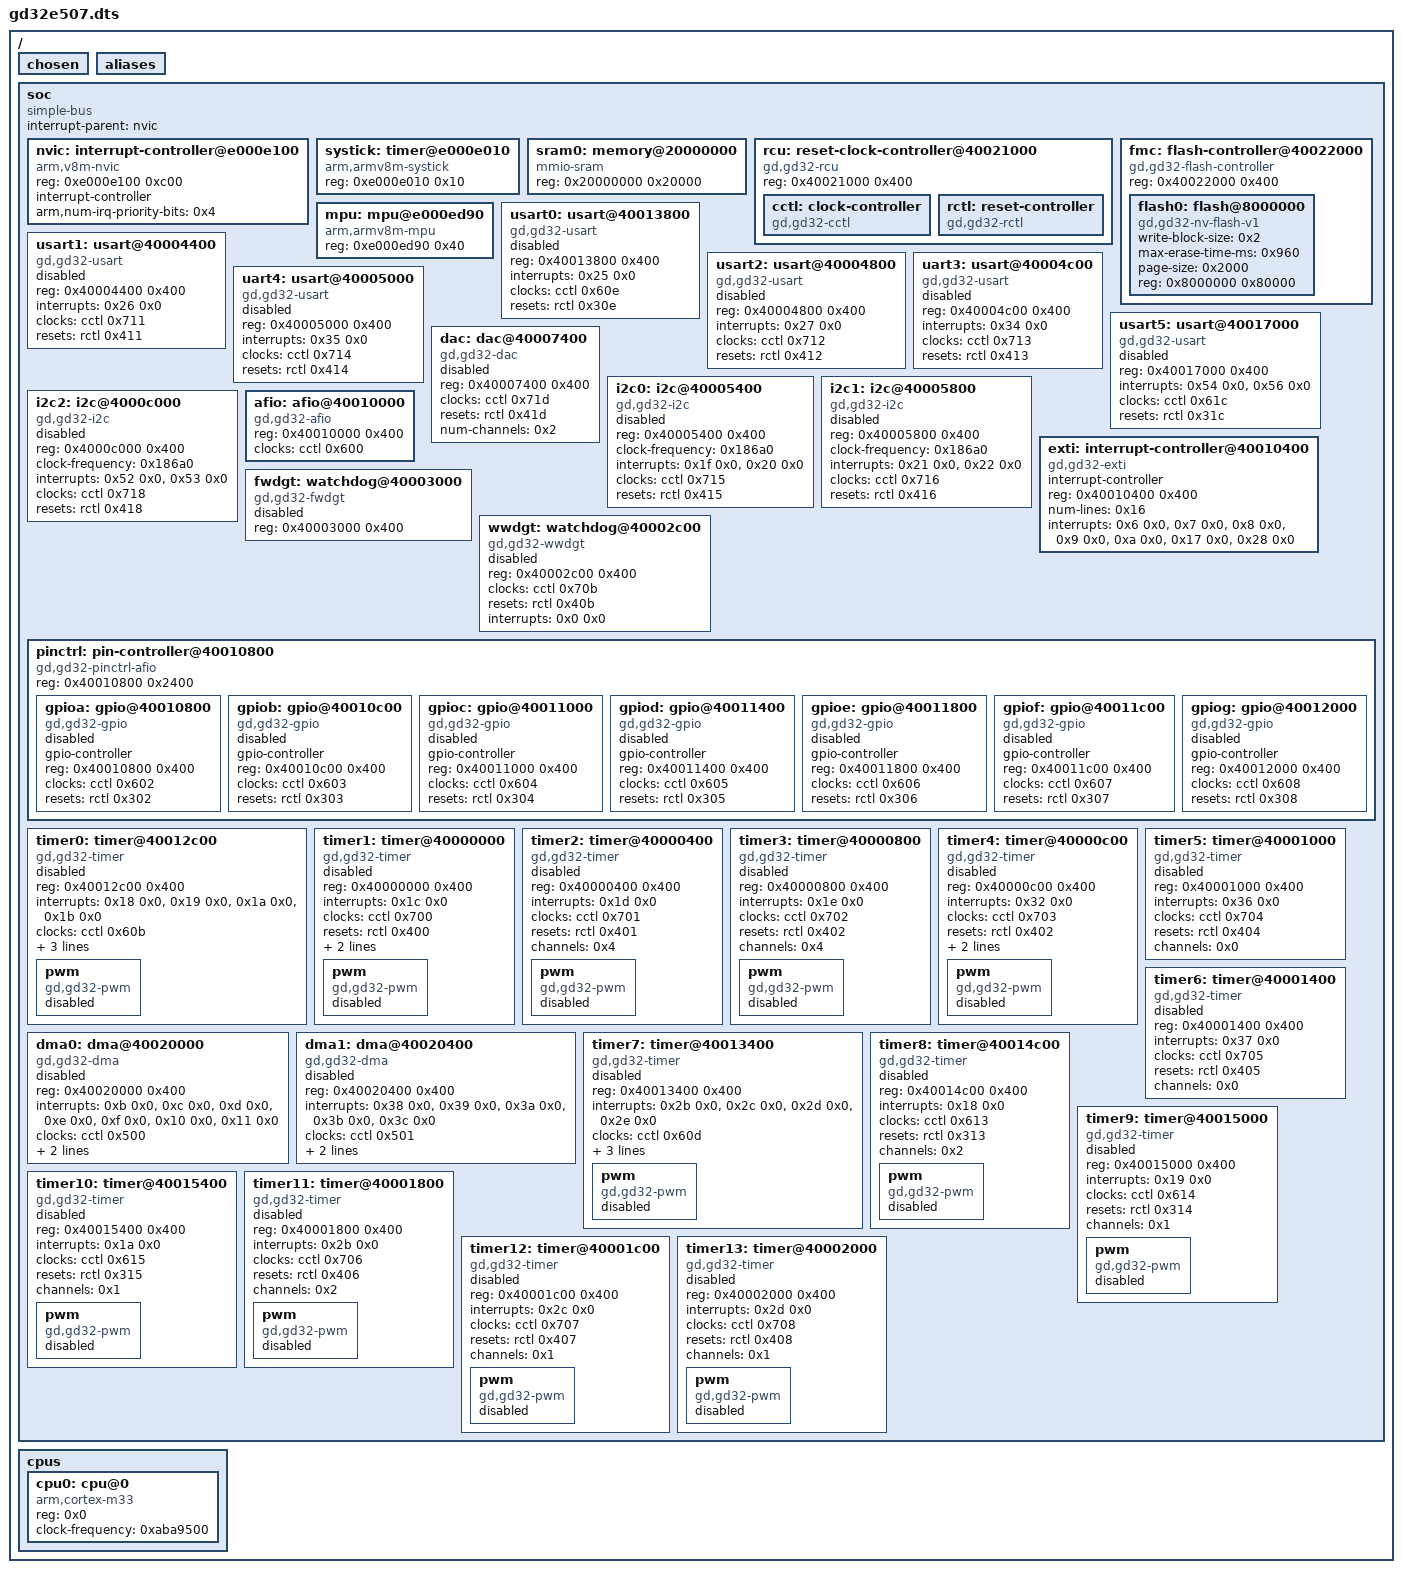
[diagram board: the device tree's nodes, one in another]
/dts-v1/;

/ {
	#address-cells = < 0x1 >;
	#size-cells = < 0x1 >;
	chosen {
	};
	aliases {
	};
	soc {
		#address-cells = < 0x1 >;
		#size-cells = < 0x1 >;
		compatible = "simple-bus";
		interrupt-parent = < &nvic >;
		ranges;
		nvic: interrupt-controller@e000e100 {
			#address-cells = < 0x1 >;
			compatible = "arm,v8m-nvic";
			reg = < 0xe000e100 0xc00 >;
			interrupt-controller;
			#interrupt-cells = < 0x2 >;
			arm,num-irq-priority-bits = < 0x4 >;
			phandle = < 0x1 >;
		};
		systick: timer@e000e010 {
			compatible = "arm,armv8m-systick";
			reg = < 0xe000e010 0x10 >;
		};
		sram0: memory@20000000 {
			compatible = "mmio-sram";
			reg = < 0x20000000 0x20000 >;
		};
		rcu: reset-clock-controller@40021000 {
			compatible = "gd,gd32-rcu";
			reg = < 0x40021000 0x400 >;
			status = "okay";
			cctl: clock-controller {
				compatible = "gd,gd32-cctl";
				#clock-cells = < 0x1 >;
				status = "okay";
				phandle = < 0x2 >;
			};
			rctl: reset-controller {
				compatible = "gd,gd32-rctl";
				#reset-cells = < 0x1 >;
				status = "okay";
				phandle = < 0x3 >;
			};
		};
		fmc: flash-controller@40022000 {
			compatible = "gd,gd32-flash-controller";
			reg = < 0x40022000 0x400 >;
			#address-cells = < 0x1 >;
			#size-cells = < 0x1 >;
			flash0: flash@8000000 {
				compatible = "gd,gd32-nv-flash-v1", "soc-nv-flash";
				write-block-size = < 0x2 >;
				max-erase-time-ms = < 0x960 >;
				page-size = < 0x2000 >;
				reg = < 0x8000000 0x80000 >;
			};
		};
		mpu: mpu@e000ed90 {
			compatible = "arm,armv8m-mpu";
			reg = < 0xe000ed90 0x40 >;
		};
		usart0: usart@40013800 {
			compatible = "gd,gd32-usart";
			reg = < 0x40013800 0x400 >;
			interrupts = < 0x25 0x0 >;
			clocks = < &cctl 0x60e >;
			resets = < &rctl 0x30e >;
			status = "disabled";
		};
		usart1: usart@40004400 {
			compatible = "gd,gd32-usart";
			reg = < 0x40004400 0x400 >;
			interrupts = < 0x26 0x0 >;
			clocks = < &cctl 0x711 >;
			resets = < &rctl 0x411 >;
			status = "disabled";
		};
		usart2: usart@40004800 {
			compatible = "gd,gd32-usart";
			reg = < 0x40004800 0x400 >;
			interrupts = < 0x27 0x0 >;
			clocks = < &cctl 0x712 >;
			resets = < &rctl 0x412 >;
			status = "disabled";
		};
		uart3: usart@40004c00 {
			compatible = "gd,gd32-usart";
			reg = < 0x40004c00 0x400 >;
			interrupts = < 0x34 0x0 >;
			clocks = < &cctl 0x713 >;
			resets = < &rctl 0x413 >;
			status = "disabled";
		};
		uart4: usart@40005000 {
			compatible = "gd,gd32-usart";
			reg = < 0x40005000 0x400 >;
			interrupts = < 0x35 0x0 >;
			clocks = < &cctl 0x714 >;
			resets = < &rctl 0x414 >;
			status = "disabled";
		};
		usart5: usart@40017000 {
			compatible = "gd,gd32-usart";
			reg = < 0x40017000 0x400 >;
			interrupts = < 0x54 0x0 >, < 0x56 0x0 >;
			interrupt-names = "global", "wkup";
			clocks = < &cctl 0x61c >;
			resets = < &rctl 0x31c >;
			status = "disabled";
		};
		dac: dac@40007400 {
			compatible = "gd,gd32-dac";
			reg = < 0x40007400 0x400 >;
			clocks = < &cctl 0x71d >;
			resets = < &rctl 0x41d >;
			num-channels = < 0x2 >;
			status = "disabled";
			#io-channel-cells = < 0x1 >;
		};
		i2c0: i2c@40005400 {
			compatible = "gd,gd32-i2c";
			reg = < 0x40005400 0x400 >;
			#address-cells = < 0x1 >;
			#size-cells = < 0x0 >;
			clock-frequency = < 0x186a0 >;
			interrupts = < 0x1f 0x0 >, < 0x20 0x0 >;
			interrupt-names = "event", "error";
			clocks = < &cctl 0x715 >;
			resets = < &rctl 0x415 >;
			status = "disabled";
		};
		i2c1: i2c@40005800 {
			compatible = "gd,gd32-i2c";
			reg = < 0x40005800 0x400 >;
			#address-cells = < 0x1 >;
			#size-cells = < 0x0 >;
			clock-frequency = < 0x186a0 >;
			interrupts = < 0x21 0x0 >, < 0x22 0x0 >;
			interrupt-names = "event", "error";
			clocks = < &cctl 0x716 >;
			resets = < &rctl 0x416 >;
			status = "disabled";
		};
		i2c2: i2c@4000c000 {
			compatible = "gd,gd32-i2c";
			reg = < 0x4000c000 0x400 >;
			#address-cells = < 0x1 >;
			#size-cells = < 0x0 >;
			clock-frequency = < 0x186a0 >;
			interrupts = < 0x52 0x0 >, < 0x53 0x0 >;
			interrupt-names = "event", "error";
			clocks = < &cctl 0x718 >;
			resets = < &rctl 0x418 >;
			status = "disabled";
		};
		exti: interrupt-controller@40010400 {
			compatible = "gd,gd32-exti";
			interrupt-controller;
			#interrupt-cells = < 0x1 >;
			reg = < 0x40010400 0x400 >;
			num-lines = < 0x16 >;
			interrupts = < 0x6 0x0 >, < 0x7 0x0 >, < 0x8 0x0 >, < 0x9 0x0 >, < 0xa 0x0 >, < 0x17 0x0 >, < 0x28 0x0 >;
			interrupt-names = "line0", "line1", "line2", "line3", "line4", "line5-9", "line10-15";
			status = "okay";
		};
		afio: afio@40010000 {
			compatible = "gd,gd32-afio";
			reg = < 0x40010000 0x400 >;
			clocks = < &cctl 0x600 >;
			status = "okay";
		};
		fwdgt: watchdog@40003000 {
			compatible = "gd,gd32-fwdgt";
			reg = < 0x40003000 0x400 >;
			status = "disabled";
		};
		wwdgt: watchdog@40002c00 {
			compatible = "gd,gd32-wwdgt";
			reg = < 0x40002c00 0x400 >;
			clocks = < &cctl 0x70b >;
			resets = < &rctl 0x40b >;
			interrupts = < 0x0 0x0 >;
			status = "disabled";
		};
		pinctrl: pin-controller@40010800 {
			compatible = "gd,gd32-pinctrl-afio";
			reg = < 0x40010800 0x2400 >;
			#address-cells = < 0x1 >;
			#size-cells = < 0x1 >;
			status = "okay";
			gpioa: gpio@40010800 {
				compatible = "gd,gd32-gpio";
				gpio-controller;
				#gpio-cells = < 0x2 >;
				reg = < 0x40010800 0x400 >;
				clocks = < &cctl 0x602 >;
				resets = < &rctl 0x302 >;
				status = "disabled";
			};
			gpiob: gpio@40010c00 {
				compatible = "gd,gd32-gpio";
				gpio-controller;
				#gpio-cells = < 0x2 >;
				reg = < 0x40010c00 0x400 >;
				clocks = < &cctl 0x603 >;
				resets = < &rctl 0x303 >;
				status = "disabled";
			};
			gpioc: gpio@40011000 {
				compatible = "gd,gd32-gpio";
				gpio-controller;
				#gpio-cells = < 0x2 >;
				reg = < 0x40011000 0x400 >;
				clocks = < &cctl 0x604 >;
				resets = < &rctl 0x304 >;
				status = "disabled";
			};
			gpiod: gpio@40011400 {
				compatible = "gd,gd32-gpio";
				gpio-controller;
				#gpio-cells = < 0x2 >;
				reg = < 0x40011400 0x400 >;
				clocks = < &cctl 0x605 >;
				resets = < &rctl 0x305 >;
				status = "disabled";
			};
			gpioe: gpio@40011800 {
				compatible = "gd,gd32-gpio";
				gpio-controller;
				#gpio-cells = < 0x2 >;
				reg = < 0x40011800 0x400 >;
				clocks = < &cctl 0x606 >;
				resets = < &rctl 0x306 >;
				status = "disabled";
			};
			gpiof: gpio@40011c00 {
				compatible = "gd,gd32-gpio";
				gpio-controller;
				#gpio-cells = < 0x2 >;
				reg = < 0x40011c00 0x400 >;
				clocks = < &cctl 0x607 >;
				resets = < &rctl 0x307 >;
				status = "disabled";
			};
			gpiog: gpio@40012000 {
				compatible = "gd,gd32-gpio";
				gpio-controller;
				#gpio-cells = < 0x2 >;
				reg = < 0x40012000 0x400 >;
				clocks = < &cctl 0x608 >;
				resets = < &rctl 0x308 >;
				status = "disabled";
			};
		};
		timer0: timer@40012c00 {
			compatible = "gd,gd32-timer";
			reg = < 0x40012c00 0x400 >;
			interrupts = < 0x18 0x0 >, < 0x19 0x0 >, < 0x1a 0x0 >, < 0x1b 0x0 >;
			interrupt-names = "brk", "up", "trgcom", "cc";
			clocks = < &cctl 0x60b >;
			resets = < &rctl 0x30b >;
			is-advanced;
			channels = < 0x4 >;
			status = "disabled";
			pwm {
				compatible = "gd,gd32-pwm";
				status = "disabled";
				#pwm-cells = < 0x3 >;
			};
		};
		timer1: timer@40000000 {
			compatible = "gd,gd32-timer";
			reg = < 0x40000000 0x400 >;
			interrupts = < 0x1c 0x0 >;
			interrupt-names = "global";
			clocks = < &cctl 0x700 >;
			resets = < &rctl 0x400 >;
			is-32bit;
			channels = < 0x4 >;
			status = "disabled";
			pwm {
				compatible = "gd,gd32-pwm";
				status = "disabled";
				#pwm-cells = < 0x3 >;
			};
		};
		timer2: timer@40000400 {
			compatible = "gd,gd32-timer";
			reg = < 0x40000400 0x400 >;
			interrupts = < 0x1d 0x0 >;
			interrupt-names = "global";
			clocks = < &cctl 0x701 >;
			resets = < &rctl 0x401 >;
			channels = < 0x4 >;
			status = "disabled";
			pwm {
				compatible = "gd,gd32-pwm";
				status = "disabled";
				#pwm-cells = < 0x3 >;
			};
		};
		timer3: timer@40000800 {
			compatible = "gd,gd32-timer";
			reg = < 0x40000800 0x400 >;
			interrupts = < 0x1e 0x0 >;
			interrupt-names = "global";
			clocks = < &cctl 0x702 >;
			resets = < &rctl 0x402 >;
			channels = < 0x4 >;
			status = "disabled";
			pwm {
				compatible = "gd,gd32-pwm";
				status = "disabled";
				#pwm-cells = < 0x3 >;
			};
		};
		timer4: timer@40000c00 {
			compatible = "gd,gd32-timer";
			reg = < 0x40000c00 0x400 >;
			interrupts = < 0x32 0x0 >;
			interrupt-names = "global";
			clocks = < &cctl 0x703 >;
			resets = < &rctl 0x402 >;
			is-32bit;
			channels = < 0x4 >;
			status = "disabled";
			pwm {
				compatible = "gd,gd32-pwm";
				status = "disabled";
				#pwm-cells = < 0x3 >;
			};
		};
		timer5: timer@40001000 {
			compatible = "gd,gd32-timer";
			reg = < 0x40001000 0x400 >;
			interrupts = < 0x36 0x0 >;
			interrupt-names = "global";
			clocks = < &cctl 0x704 >;
			resets = < &rctl 0x404 >;
			channels = < 0x0 >;
			status = "disabled";
		};
		timer6: timer@40001400 {
			compatible = "gd,gd32-timer";
			reg = < 0x40001400 0x400 >;
			interrupts = < 0x37 0x0 >;
			interrupt-names = "global";
			clocks = < &cctl 0x705 >;
			resets = < &rctl 0x405 >;
			channels = < 0x0 >;
			status = "disabled";
		};
		dma0: dma@40020000 {
			compatible = "gd,gd32-dma";
			reg = < 0x40020000 0x400 >;
			interrupts = < 0xb 0x0 >, < 0xc 0x0 >, < 0xd 0x0 >, < 0xe 0x0 >, < 0xf 0x0 >, < 0x10 0x0 >, < 0x11 0x0 >;
			clocks = < &cctl 0x500 >;
			dma-channels = < 0x7 >;
			gd,mem2mem;
			#dma-cells = < 0x2 >;
			status = "disabled";
		};
		dma1: dma@40020400 {
			compatible = "gd,gd32-dma";
			reg = < 0x40020400 0x400 >;
			interrupts = < 0x38 0x0 >, < 0x39 0x0 >, < 0x3a 0x0 >, < 0x3b 0x0 >, < 0x3c 0x0 >;
			clocks = < &cctl 0x501 >;
			dma-channels = < 0x5 >;
			gd,mem2mem;
			#dma-cells = < 0x2 >;
			status = "disabled";
		};
		timer7: timer@40013400 {
			compatible = "gd,gd32-timer";
			reg = < 0x40013400 0x400 >;
			interrupts = < 0x2b 0x0 >, < 0x2c 0x0 >, < 0x2d 0x0 >, < 0x2e 0x0 >;
			interrupt-names = "brk", "up", "trgcom", "cc";
			clocks = < &cctl 0x60d >;
			resets = < &rctl 0x30d >;
			is-advanced;
			channels = < 0x4 >;
			status = "disabled";
			pwm {
				compatible = "gd,gd32-pwm";
				status = "disabled";
				#pwm-cells = < 0x3 >;
			};
		};
		timer8: timer@40014c00 {
			compatible = "gd,gd32-timer";
			reg = < 0x40014c00 0x400 >;
			interrupts = < 0x18 0x0 >;
			interrupt-names = "global";
			clocks = < &cctl 0x613 >;
			resets = < &rctl 0x313 >;
			channels = < 0x2 >;
			status = "disabled";
			pwm {
				compatible = "gd,gd32-pwm";
				status = "disabled";
				#pwm-cells = < 0x3 >;
			};
		};
		timer9: timer@40015000 {
			compatible = "gd,gd32-timer";
			reg = < 0x40015000 0x400 >;
			interrupts = < 0x19 0x0 >;
			interrupt-names = "global";
			clocks = < &cctl 0x614 >;
			resets = < &rctl 0x314 >;
			channels = < 0x1 >;
			status = "disabled";
			pwm {
				compatible = "gd,gd32-pwm";
				status = "disabled";
				#pwm-cells = < 0x3 >;
			};
		};
		timer10: timer@40015400 {
			compatible = "gd,gd32-timer";
			reg = < 0x40015400 0x400 >;
			interrupts = < 0x1a 0x0 >;
			interrupt-names = "global";
			clocks = < &cctl 0x615 >;
			resets = < &rctl 0x315 >;
			channels = < 0x1 >;
			status = "disabled";
			pwm {
				compatible = "gd,gd32-pwm";
				status = "disabled";
				#pwm-cells = < 0x3 >;
			};
		};
		timer11: timer@40001800 {
			compatible = "gd,gd32-timer";
			reg = < 0x40001800 0x400 >;
			interrupts = < 0x2b 0x0 >;
			interrupt-names = "global";
			clocks = < &cctl 0x706 >;
			resets = < &rctl 0x406 >;
			channels = < 0x2 >;
			status = "disabled";
			pwm {
				compatible = "gd,gd32-pwm";
				status = "disabled";
				#pwm-cells = < 0x3 >;
			};
		};
		timer12: timer@40001c00 {
			compatible = "gd,gd32-timer";
			reg = < 0x40001c00 0x400 >;
			interrupts = < 0x2c 0x0 >;
			interrupt-names = "global";
			clocks = < &cctl 0x707 >;
			resets = < &rctl 0x407 >;
			channels = < 0x1 >;
			status = "disabled";
			pwm {
				compatible = "gd,gd32-pwm";
				status = "disabled";
				#pwm-cells = < 0x3 >;
			};
		};
		timer13: timer@40002000 {
			compatible = "gd,gd32-timer";
			reg = < 0x40002000 0x400 >;
			interrupts = < 0x2d 0x0 >;
			interrupt-names = "global";
			clocks = < &cctl 0x708 >;
			resets = < &rctl 0x408 >;
			channels = < 0x1 >;
			status = "disabled";
			pwm {
				compatible = "gd,gd32-pwm";
				status = "disabled";
				#pwm-cells = < 0x3 >;
			};
		};
	};
	cpus {
		#address-cells = < 0x1 >;
		#size-cells = < 0x0 >;
		cpu0: cpu@0 {
			compatible = "arm,cortex-m33";
			reg = < 0x0 >;
			#address-cells = < 0x1 >;
			#size-cells = < 0x1 >;
			clock-frequency = < 0xaba9500 >;
		};
	};
};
